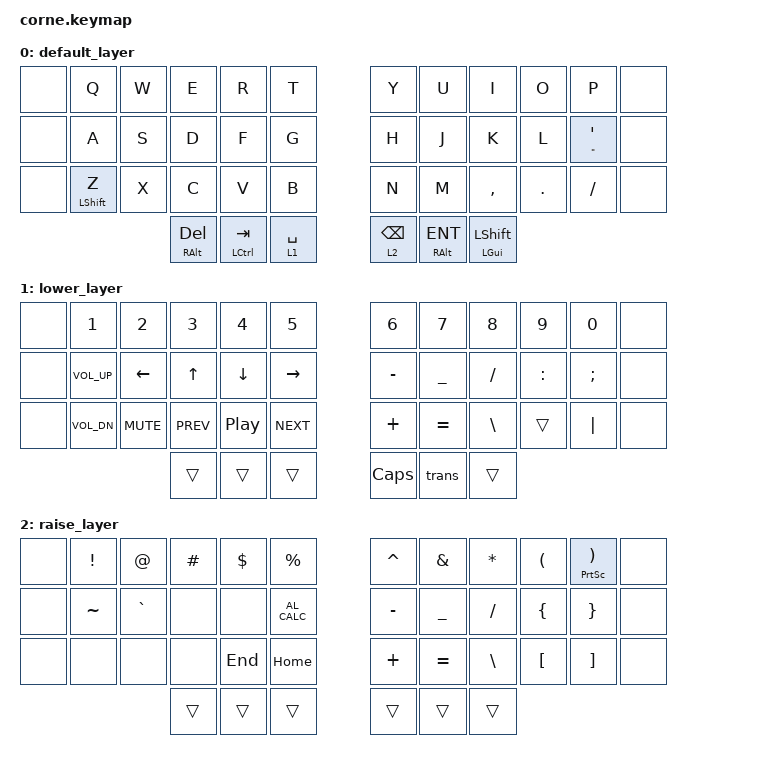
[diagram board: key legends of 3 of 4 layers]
/*
 * Copyright (c) 2020 The ZMK Contributors
 *
 * SPDX-License-Identifier: MIT
 */

#include <behaviors.dtsi>
#include <dt-bindings/zmk/keys.h>
#include <dt-bindings/zmk/bt.h>

/ {
    combos {
        compatible = "zmk,combos";
        combo_esc {
            timeout-ms = <50>;
            key-positions = <1 2>;
            bindings = <&kp ESC>;
            };
         };
    combos {
        compatible = "zmk,combos";
        combo_layer {
            timeout-ms = <50>;
            key-positions = <38 39>;
            bindings = <&mo 3>;
            };
         };

        keymap {
                compatible = "zmk,keymap";

                default_layer {
// -----------------------------------------------------------------------------------------
// |      |Q,ESC |W,ESC|  E  |  R  |  T  |   |  Y  |  U   |  I  |  O  |  P  |      |
// |      |  A   |  S  |  D  |  F  |  G  |   |  H  |  J   |  K  |  L  | ' " |      |
// |      |Z,SHFT|  X  |  C  |  V  |  B  |   |  N  |  M   |  ,  |  .  | /?  |      |
//            |ALT/DEL|CTRL/TAB|SPC/LOWER|   |BSP/RAISE|ALT/ENT|SHFT/GUI|
                        bindings = <
   &none &kp Q       &kp W &kp E &kp R &kp T     &kp Y &kp U  &kp I     &kp O   &kp P    &none
   &none &kp A       &kp S &kp D &kp F &kp G     &kp H &kp J  &kp K     &kp L   &mt DQT APOS  &none
   &none &mt LSHFT Z &kp X &kp C &kp V &kp B     &kp N &kp M  &kp COMMA &kp DOT &kp FSLH &none
   &mt RALT DEL &mt LCTRL TAB  &lt 1 SPACE   &lt 2 BSPC  &mt RALT ENT  &mt LGUI LSHFT
                        >;
                };
                lower_layer {
// -----------------------------------------------------------------------------------------
// |      |  1  |  2  |  3  |  4  |  5  |   |  6  |  7  |  8  |  9  |  0  |     |
// |      | VUP | LFT | UP  | DWN | RGT |   |  -  |  _  |  /  |  :  |  ;  |     |  
// |      | VDN |MUTE | RWD | PP  | NXT |   |  +  |  =  |  \  |  .  |  |  |     |  
//                    |     |     |     |   | CAP |     |     |
                        bindings = <
   &none  &kp N1       &kp N2     &kp N3     &kp N4    &kp N5        &kp N6     &kp N7   &kp N8   &kp N9 &kp N0    &none                 
   &none  &kp C_VOL_UP &kp LEFT   &kp UP     &kp DOWN  &kp RIGHT     &kp MINUS &kp UNDER &kp FSLH &kp COLON  &kp SEMI  &none
   &none  &kp C_VOL_DN &kp C_MUTE &kp C_PREV &kp C_PP  &kp C_NEXT    &kp PLUS  &kp EQUAL &kp BSLH &trans  &kp PIPE &none
                                            &trans &trans &trans     &kp CAPS  trans  &trans
                        >;
                };

                raise_layer {
// -----------------------------------------------------------------------------------------
// |      |  !  |  @  |  #  |  $  |  %  |   |  ^  |  &  |  *  |  (  | )PSCRN|     | 
// |      |  ~  |  `  |     |     | CALC|   |  -  |  _  |  /  |  {  |   }   |     |
// |      |     |     |     | END | HOME|   |  +  |  =  |  \  |  [  |   ]   |     |
//                    |     | ESC |     |   | CAP |     |     |
                        bindings = <
                        
   &none  &kp EXCL  &kp AT    &kp HASH &kp DLLR &kp PRCNT        &kp CARET &kp AMPS   &kp STAR &kp LPAR &mt PSCRN RPAR &none
   &none  &kp TILDE &kp GRAVE &none    &none    &kp C_AL_CALC    &kp MINUS &kp UNDER &kp FSLH &kp LBRC &kp RBRC &none
   &none  &none     &none     &none    &kp END  &kp HOME         &kp PLUS  &kp EQUAL &kp BSLH &kp LBKT &kp RBKT &none
                                      &trans &trans &trans       &trans &trans &trans
                        >;
                };

                adjust_layer {
// -----------------------------------------------------------------------------------------
// |      | F1  | F2  |  F3 | F4  | F5  |   | F6  | F7  |  F8 | F9  | F10 |     |
// |      | BT1 | BT2 |     |     |     |   |     |     |     | F11 | F12 |     |
// |      |BTCLR|     |     |     |     |   |     |     |     |     |     |     |
//                    |     |     |     |   |     |     |     |
                        bindings = <
   &none &kp F1       &kp F2    &kp F3 &kp F4 &kp F5      &kp F6 &kp F7 &kp F8 &kp F9 &kp F10 &none
   &none &bt BT_SEL 1 &bt BT_SEL 2 &none &none &none      &none &none &none &kp F11 &kp F12 &none
   &none &bt BT_CLR   &none        &none &none &none      &none &none &none &none &none &none &none
                                &trans &trans &trans      &trans   &trans   &trans
                        >;
              };
        };
};
